# CY8C5868AXI_LP035 register map
File version: 0.1
CY8C58LP
Registers are 8-bit, read-write, no defined reset value unless marked. A register's access mark holds for its fields unless they carry their own. Offsets are from the block's base; lines under a group give offsets from that group; [hi:lo] are bit positions; {n}, {i} and the like mark numbered series; 'fields as' and 'values as' point back to an identical list; <NAME> marks a mode.

## Memory map
0x00000000 STOP
0x00000000 MODE
0x00000000 LED
0x00000000 UART_1 — UART
0x00000000 PWM
0x00000000 UART_3 — UART
0x00000000 PWM_1
0x00000000 UART_4 — UART
0x00000000 Timer
0x00000000 UART_2 — UART

## STOP
Base 0x00000000
0x4000647F STOP_CONTROL_REG

## MODE
Base 0x00000000
0x40006575 MODE_CONTROL_REG

## LED
Base 0x00000000
0x4000647E LED_CONTROL_REG

## UART_1 — UART
Base 0x00000000
0x40006423 RX_UART_1_RX_ADDRESS1 — RX Address1 Register
0x40006433 RX_UART_1_RX_ADDRESS2 — RX Address2 Register
0x40006443 RX_UART_1_RX_DATA — RX Data Register
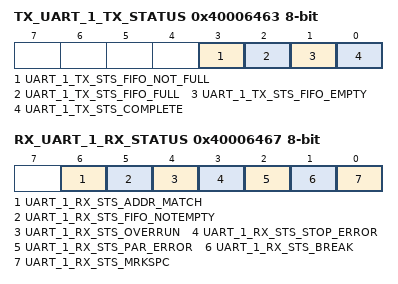
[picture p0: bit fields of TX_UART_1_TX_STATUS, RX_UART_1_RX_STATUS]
0x40006463 TX_UART_1_TX_STATUS — TX status register
  [3] UART_1_TX_STS_FIFO_NOT_FULL ro, [2] UART_1_TX_STS_FIFO_FULL ro, [1] UART_1_TX_STS_FIFO_EMPTY ro, [0] UART_1_TX_STS_COMPLETE ro
0x40006467 RX_UART_1_RX_STATUS — RX status register
  [6] UART_1_RX_STS_ADDR_MATCH ro, [5] UART_1_RX_STS_FIFO_NOTEMPTY ro, [4] UART_1_RX_STS_OVERRUN ro, [3] UART_1_RX_STS_STOP_ERROR ro, [2] UART_1_RX_STS_PAR_ERROR ro, [1] UART_1_RX_STS_BREAK ro, [0] UART_1_RX_STS_MRKSPC ro
0x40006547 TX_UART_1_TX_DATA — TX Data Register

## PWM
Base 0x00000000
0x4000642A PWM_COMPARE_Reg_ — UDB.D0 - Assigned Compare Value
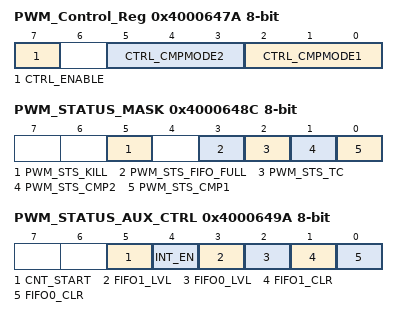
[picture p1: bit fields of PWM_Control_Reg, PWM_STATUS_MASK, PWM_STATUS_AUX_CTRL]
0x4000647A PWM_Control_Reg — UDB Control Register - Assigned Control Register Value
  [7] CTRL_ENABLE — Enable the PWM
  [5:3] CTRL_CMPMODE2 — Compare mode 2
  [2:0] CTRL_CMPMODE1 — Compare mode 1
0x4000648C PWM_STATUS_MASK — UDB Status bits Interrupt Mask Enable Register
  [5] PWM_STS_KILL ro — Enables the Interrupt on Kill
  [3] PWM_STS_FIFO_FULL ro — FIFO Full Status Mask
  [2] PWM_STS_TC ro — Enables the Interrupt on Terminal Count
  [1] PWM_STS_CMP2 ro — Enables the Interrupt on Compare 2
  [0] PWM_STS_CMP1 ro — Enables the Interrupt on Compare 1
0x4000649A PWM_STATUS_AUX_CTRL — UDB Auxilliary Control Register
  [5] CNT_START — FIFO0 clear
    0=E_CNT_START0 (Disable counter); 1=E_CNT_START1 (Enable counter)
  [4] INT_EN
    0=E_INT_EN0 (Interrupt disabled); 1=E_INT_EN1 (Interrupt enabled)
  [3] FIFO1_LVL — FIFO level
    0=E_FIFO_LVL_0 (FIFO LVL: input mode: FIFO not full; output mode: FIFO not empty); 1=E_FIFO_LVL_1 (FIFO LVL: input mode: FIFO at least 1/2 empty; output mode: FIFO at least 1/2 full)
  [2] FIFO0_LVL — FIFO level
    values as FIFO1_LVL
  [1] FIFO1_CLR — FIFO1 clear
    0=E_FIFO_CLR_0 (Normal FIFO operation); 1=E_FIFO_CLR_1 (Clear FIFO state)
  [0] FIFO0_CLR — FIFO0 clear
    values as FIFO1_CLR

## UART_3 — UART
Base 0x00000000
0x40006421 RX_UART_3_RX_ADDRESS1 — RX Address1 Register
0x40006431 RX_UART_3_RX_ADDRESS2 — RX Address2 Register
0x40006441 RX_UART_3_RX_DATA — RX Data Register
0x4000644D TX_UART_3_TX_DATA — TX Data Register
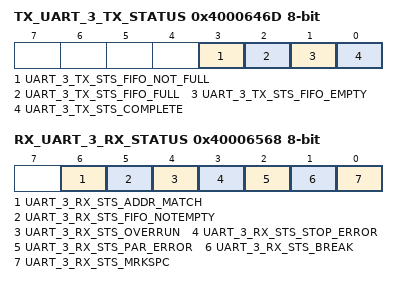
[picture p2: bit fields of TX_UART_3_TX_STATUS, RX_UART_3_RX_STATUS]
0x4000646D TX_UART_3_TX_STATUS — TX status register
  [3] UART_3_TX_STS_FIFO_NOT_FULL ro, [2] UART_3_TX_STS_FIFO_FULL ro, [1] UART_3_TX_STS_FIFO_EMPTY ro, [0] UART_3_TX_STS_COMPLETE ro
0x40006568 RX_UART_3_RX_STATUS — RX status register
  [6] UART_3_RX_STS_ADDR_MATCH ro, [5] UART_3_RX_STS_FIFO_NOTEMPTY ro, [4] UART_3_RX_STS_OVERRUN ro, [3] UART_3_RX_STS_STOP_ERROR ro, [2] UART_3_RX_STS_PAR_ERROR ro, [1] UART_3_RX_STS_BREAK ro, [0] UART_3_RX_STS_MRKSPC ro

## PWM_1
Base 0x00000000
0x40006524 PWM_1_COMPARE_Reg_ — UDB.D0 - Assigned Compare Value
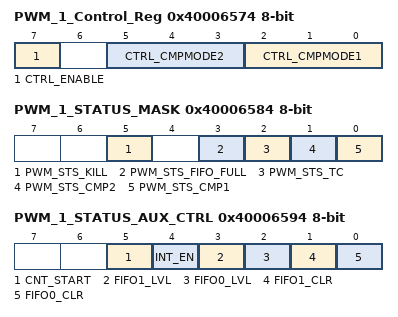
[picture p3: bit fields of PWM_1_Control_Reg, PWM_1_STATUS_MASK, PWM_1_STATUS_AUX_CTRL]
0x40006574 PWM_1_Control_Reg — UDB Control Register - Assigned Control Register Value
  [7] CTRL_ENABLE — Enable the PWM
  [5:3] CTRL_CMPMODE2 — Compare mode 2
  [2:0] CTRL_CMPMODE1 — Compare mode 1
0x40006584 PWM_1_STATUS_MASK — UDB Status bits Interrupt Mask Enable Register
  fields as PWM.PWM_STATUS_MASK
0x40006594 PWM_1_STATUS_AUX_CTRL — UDB Auxilliary Control Register
  fields as PWM.PWM_STATUS_AUX_CTRL

## UART_4 — UART
Base 0x00000000
0x40006424 RX_UART_4_RX_ADDRESS1 — RX Address1 Register
0x40006434 RX_UART_4_RX_ADDRESS2 — RX Address2 Register
0x40006444 RX_UART_4_RX_DATA — RX Data Register
0x4000644F TX_UART_4_TX_DATA — TX Data Register
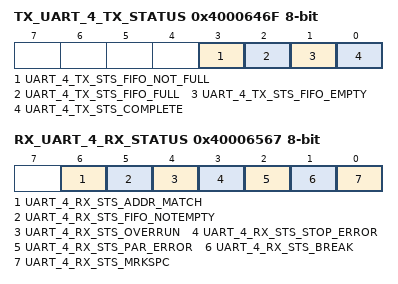
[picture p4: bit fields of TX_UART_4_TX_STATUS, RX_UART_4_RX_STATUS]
0x4000646F TX_UART_4_TX_STATUS — TX status register
  [3] UART_4_TX_STS_FIFO_NOT_FULL ro, [2] UART_4_TX_STS_FIFO_FULL ro, [1] UART_4_TX_STS_FIFO_EMPTY ro, [0] UART_4_TX_STS_COMPLETE ro
0x40006567 RX_UART_4_RX_STATUS — RX status register
  [6] UART_4_RX_STS_ADDR_MATCH ro, [5] UART_4_RX_STS_FIFO_NOTEMPTY ro, [4] UART_4_RX_STS_OVERRUN ro, [3] UART_4_RX_STS_STOP_ERROR ro, [2] UART_4_RX_STS_PAR_ERROR ro, [1] UART_4_RX_STS_BREAK ro, [0] UART_4_RX_STS_MRKSPC ro

## Timer
Base 0x00000000
0x40006508 Timer_COUNTER 16-bit — UDB.A0 - Current Down Counter Value
0x40006528 Timer_PERIOD 16-bit — UDB.D0 - Assigned Period
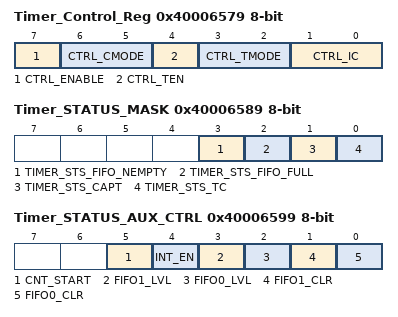
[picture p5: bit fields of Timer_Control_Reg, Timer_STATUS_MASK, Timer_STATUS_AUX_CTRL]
0x40006579 Timer_Control_Reg — UDB Control Register - Assigned Control Register Value
  [7] CTRL_ENABLE — Enable the Timer
  [6:5] CTRL_CMODE — Capture Mode
  [4] CTRL_TEN — Trigger Enable Bit
  [3:2] CTRL_TMODE — Trigger Mode
  [1:0] CTRL_IC — Interrupt Count
0x40006589 Timer_STATUS_MASK — UDB Status bits Interrupt Mask Enable Register
  [3] TIMER_STS_FIFO_NEMPTY ro — FIFO Empty status
  [2] TIMER_STS_FIFO_FULL ro — FIFO Full Status
  [1] TIMER_STS_CAPT ro — Enables the Interrupt on Capture
  [0] TIMER_STS_TC ro — Enables the Interrupt on TC
0x40006599 Timer_STATUS_AUX_CTRL — UDB Auxilliary Control Register
  fields as PWM.PWM_STATUS_AUX_CTRL

## UART_2 — UART
Base 0x00000000
0x40006422 RX_UART_2_RX_ADDRESS1 — RX Address1 Register
0x40006432 RX_UART_2_RX_ADDRESS2 — RX Address2 Register
0x40006442 RX_UART_2_RX_DATA — RX Data Register
0x40006545 TX_UART_2_TX_DATA — TX Data Register
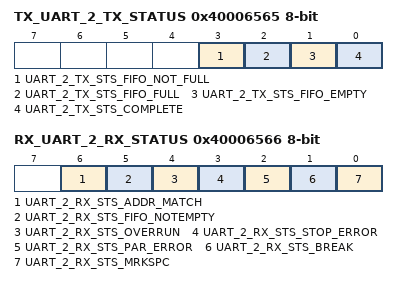
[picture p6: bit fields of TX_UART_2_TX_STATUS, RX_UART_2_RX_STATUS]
0x40006565 TX_UART_2_TX_STATUS — TX status register
  [3] UART_2_TX_STS_FIFO_NOT_FULL ro, [2] UART_2_TX_STS_FIFO_FULL ro, [1] UART_2_TX_STS_FIFO_EMPTY ro, [0] UART_2_TX_STS_COMPLETE ro
0x40006566 RX_UART_2_RX_STATUS — RX status register
  [6] UART_2_RX_STS_ADDR_MATCH ro, [5] UART_2_RX_STS_FIFO_NOTEMPTY ro, [4] UART_2_RX_STS_OVERRUN ro, [3] UART_2_RX_STS_STOP_ERROR ro, [2] UART_2_RX_STS_PAR_ERROR ro, [1] UART_2_RX_STS_BREAK ro, [0] UART_2_RX_STS_MRKSPC ro
